# Montana register map
Vendor: ONSemiconductor; Series: Montana Series; File version: 1.0
CPU: CM33 r0p4, little endian, MPU, FPU, 3 interrupt priority bits
Registers are 32-bit, read-write, reset 0x0 unless marked. A register's access mark holds for its fields unless they carry their own. Offsets are from the block's base; [hi:lo] are bit positions; {n}, {i} and the like mark numbered series.

## NFC — NFC Controller
Base 0x40040000
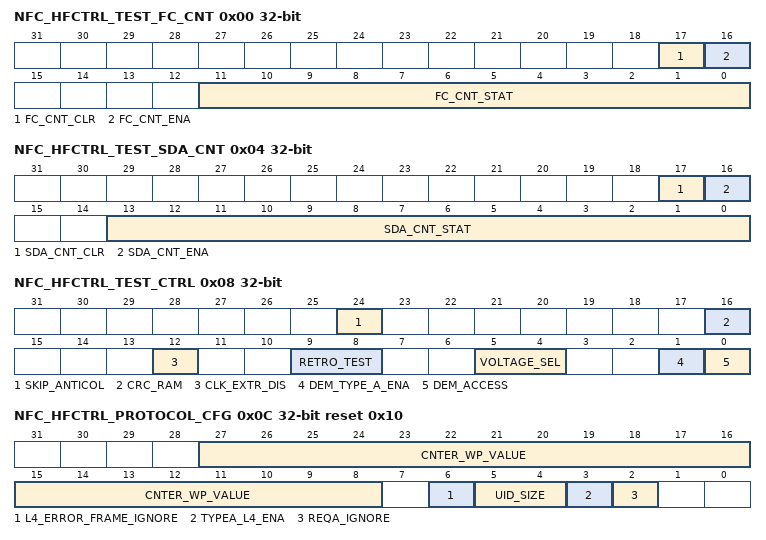
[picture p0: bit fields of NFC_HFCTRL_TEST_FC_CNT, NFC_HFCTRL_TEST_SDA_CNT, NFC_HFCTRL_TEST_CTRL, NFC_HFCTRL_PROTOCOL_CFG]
0x00 NFC_HFCTRL_TEST_FC_CNT — TEST Fc COUNTER Register
  [17] FC_CNT_CLR — Pulse to clear the FC_CNT_STATUS value to 0xFFF Set Only by SW; reset by HW
    0=FC_CNT_NOT_CLR; 1=FC_CNT_CLR
  [16] FC_CNT_ENA — Stop/decounting the decounter
    0=FC_CNT_STOP; 1=FC_CNT_DECOUNTING
  [11:0] FC_CNT_STAT ro — Fc clock counter status
    0=FC_CNT_STATUS_VALUE
0x04 NFC_HFCTRL_TEST_SDA_CNT — TEST SDA COUNTER Register
  [17] SDA_CNT_CLR — Pulse to clear the SDA_CNT_STATUS value to 0x0000. Set Only by SW; reset by HW
    0=SDA_CNT_NOT_CLR; 1=SDA_CNT_CLR
  [16] SDA_CNT_ENA — SDA counter enable
    0=SDA_CNT_STOP (The counter is stopped); 1=SDA_CNT_COUNTING (The counter is counting)
  [13:0] SDA_CNT_STAT ro — SDA clock counter
    0=SDA_CNT_STATUS_VALUE
0x08 NFC_HFCTRL_TEST_CTRL — TEST CTRL Register
  [24] SKIP_ANTICOL — 0 : When ISO Type A; the Layer 3 anti-collision sequence is managed by the HW FSM 1 : When ISO Type A; the Layer 3 anti-collision sequence is skipped with direct SW access
    0=ANTICOL_MANAGED; 1=ANTICOL_SKIPPED
  [16] CRC_RAM — 1 : The CRC is taken from the last 2 bytes of the IO RAM buffer (TEST mode) 0 : The FSM generates on the fly the CRC from the data information present inside the IO RAM buffer
    0=CRC_READ_FROM_RAM; 1=CRC_PROCESS
  [12] CLK_EXTR_DIS — When 1; the clock extractor of the Analog Front end is disabled (power saving configuration when HF not used)
    0=CLK_EXTRACTOR_ENABLED; 1=CLK_EXTRACTOR_DISABLED
  [9:8] RETRO_TEST — retromodulation control testing features 00 : retro is monitored by the FSM 01 : retro=1 (TEST mode or power saving configuration when HF not used) 10 : retro=Fc/16 (TEST mode) 11 : retro=Fc/8 (TEST mode)
    0=FSM_CTRL_RETRO; 1=RETRO_SET; 2=RETRO_AT_FC_DIV_16; 3=RETRO_AT_FC_DIV_8
  [5:4] VOLTAGE_SEL — Voltage selection for Analog Testing PAD redirection
    0=SEL_HIGH_Z; 1=SEL_VDC; 2=SEL_VDDA
  [1] DEM_TYPE_A_ENA — Only active when DEM_ACCESS=1 1 : Enable the demodulator Type A analog front-end (Rx) 0 : Disable the demodulator Type A analog front-end
    0=DEM_TYPE_A_DISABLED; 1=DEM_TYPE_A_ENABLED
  [0] DEM_ACCESS — 1 : The SW has the hand to enable or disable the demodulators (TEST mode) 0 : The FSM of the digital controller has the hand on demodulators activation according to PROTOCOL_CFG.TYPE
    0=HW_DEM_ACCESS; 1=SW_DEM_ACCESS
0x0C NFC_HFCTRL_PROTOCOL_CFG reset 0x10 — PROTOCOL and COMMUNICATION CONFIG register
  [27:8] CNTER_WP_VALUE — Slot counter watchpoint value (FDT PCD to PICC)
    0=CNTER_WP_RESET_VALUE
  [6] L4_ERROR_FRAME_IGNORE — Layer 4 Transmission Error frame ignore
    0=L4_ERROR_FRAME_REPORT_ALL; 1=L4_ERROR_FRAME_IGNORE
  [5:4] UID_SIZE — UID size when Type A (Layer 3) 01: UID size=1 10: UID size=2 11: UID size=3 00: not applicable
  [3] TYPEA_L4_ENA — The SW shall set this bit to 1 when entering in ISO Type A Layer 4 0: only 64 bytes are available for SW (0xE000-0xE0FF) 1: the 1 Kbytes of the IO RAM are available Autoclear by HW when BACK_TO_HALT
    0=TYPEA_L4_DISABLED; 1=TYPEA_L4_ENABLED
  [2] REQA_IGNORE — The SW shall set this bit to 1 after the first valid RATS or C-RATS 0: a BACK_TO_HALT will make the HW FSM in IDLE state (like after POR). 1: a BACK_TO_HALT will make the HW FSM in HALT state.
    0=BACK_TO_IDLE; 1=BACK_TO_HALT
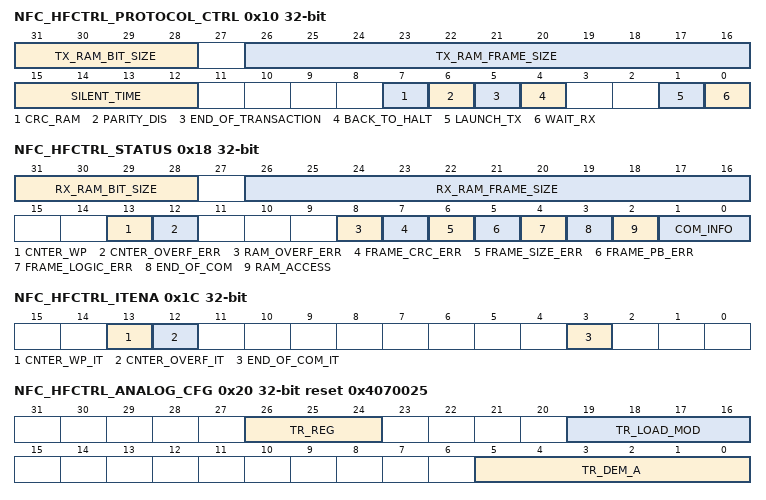
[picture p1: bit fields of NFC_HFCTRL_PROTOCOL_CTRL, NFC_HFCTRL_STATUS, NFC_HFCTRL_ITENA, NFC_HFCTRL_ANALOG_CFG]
0x10 NFC_HFCTRL_PROTOCOL_CTRL — PROTOCOL and COMMUNICATION CTRL Register
  [31:28] TX_RAM_BIT_SIZE — The number of split byte bits sent is 8-TX_RAM_BIT_SIZE
  [26:16] TX_RAM_FRAME_SIZE — IO RAM frame size status for Tx : To be updated by SW before/when LAUNCH_TX
  [15:12] SILENT_TIME — Silent time value for the current communication sequence Defined in number of slots
  [7] CRC_RAM — '1' : Tx only. No CRC bytes added at end of frame, final size is TX_RAM_FRAME_SIZE
    1=CRC_RAM_DISABLED
  [6] PARITY_DIS — '1' : Tx only. Parity bit is not sent
    1=PARITY_DISABLED
  [5] END_OF_TRANSACTION — Indicates the end of transaction
    1=END_OF_TRANSACTION
  [4] BACK_TO_HALT — When 1: Allows to return in IDLE/HALT ISO Type A layer 3 - If launched with WAIT_RX: PICC mode is in HALT or IDLE state immediately - If launched with LAUNCH_TX: the HALT or IDLE state will be reached after the end of the Tx frame The IDLE or HALT state is chosen with the REQA_IGNORE configuration Set Only by SW; reset by HW
    1=RETURN_TO_HALT_OR_IDLE
  [1] LAUNCH_TX — Launch the Tx frame with the IO RAM buffer content after waiting SILENT_TIME slots Set Only by SW; reset by HW
  [0] WAIT_RX — When STATUS.COM_INFO=00; launch the HF digital controller; according to the HFCTRL_PROTOCOL_CFG.TYPE configuration When STATUS.COM_INFO=11; it will force the Tx frame ignorance : the PICC will not answer (mute); the HF digital controller returns in Rx mode This bit shall not be launched when STATUS.COM_INFO=01 or 10 Note that at each WAIT_RX=1; the bit rates configurations are reloaded inside the digital controller Set Only by SW; reset by HW
0x14 NFC_HFCTRL_COUNTER_STATUS ro — SLOT COUNTER STATUS register
  [19:0] CNTER_STATUS — Slot counter status (FDT PDC to PICC)
    0=CNTER_STATUS_VALUE
0x18 NFC_HFCTRL_STATUS ro — STATUS Register
  [31:28] RX_RAM_BIT_SIZE — IO RAM bit size part status when Rx Updated when Rx to Exec period transition
    0=RX_RAM_BIT_SIZE_VALUE
  [26:16] RX_RAM_FRAME_SIZE — IO RAM frame size status when Rx Updated by the HW
    0=RX_RAM_FRAME_SIZE_VALUE
  [13] CNTER_WP — Slot counter Watchpoint flag When 1; the Slot counter has reached the value of the watchpoint in Exec period Clear only by SW
    0=NO_CNT_WP_ERROR; 1=CNT_WP_ERROR
  [12] CNTER_OVERF_ERR — Slot counter Overflow error flag When 1; the Slot counter has reached the maximum value and continues counting from 0 Clear only by SW
    0=NO_CNT_OVERUN_ERROR; 1=CNT_OVERRUN_ERROR
  [8] RAM_OVERF_ERR — IO RAM overflow error flag When 1; the complete 1KB IO RAM buffer has been filled by the Rx frame Clear only by SW
    1=RAM_FULL
  [7] FRAME_CRC_ERR — Bad frame CRC error flag : CRC on two bytes; done in the whole byte of the frame (ISO type B / ISO type A layer 4) in Rx When 1; a CRC error has been detected Clear only by SW
    0=NO_CRC_ERROR; 1=CRC_ERROR
  [6] FRAME_SIZE_ERR — Frame size error flag : not standard frame size (ISO type B / ISO type A layer 4) in Rx. When 1; a frame size error has been detected Clear only by SW
    0=NO_FRAME_SIZE_ERROR; 1=FRAME_SIZE_ERROR
  [5] FRAME_PB_ERR — Parity bit error flag when ISO type B / ISO type A layer 4 Rx When 1; a parity bit error has been detected inside the frame Clear only by SW
    0=NO_PARITY_ERROR; 1=PARITY_ERROR
  [4] FRAME_LOGIC_ERR — Logic error flag when ISO type B / ISO type A layer 4 Rx When 1; an logic bit error has been detected inside the frame Clear only by SW
    0=NO_LOGIC_ERROR; 1=LOGIC_ERROR
  [3] END_OF_COM — When '1', the Rx period has finished (end of reception) or the Tx transmission has finished with the end of transaction feature activated. It is only updated with the presence of the SClk and it is automatically set/reset by HW.
    0=NOT_END_OF_COM
  [2] RAM_ACCESS — IO RAM access right for SW status When 1: The IO RAM can be accessed by SW for read and write
    0=SW_CAN_T_ACCESS_RAM; 1=SW_COULD_ACCESS_RAM
  [1:0] COM_INFO — Communication state status 00: Digital controller not launched (HFCTRL_PROTOCOL_CTRL .WAIT_RX) 01: Rx state 10: Tx state 11: Exec state Whatever the layer is.
    0=IDLE_STATE; 1=RX_STATE; 2=TX_STATE; 3=EXEC_STATE
0x1C NFC_HFCTRL_ITENA — ITENA Interrupt enable register
  [13] CNTER_WP_IT — 1: An interruption is raised when CNTER_WP set to 1 0: The interruption for this flag is disabled
    0=CNT_WP_INT_DISABLE; 1=CNT_WP_INT_ENABLE
  [12] CNTER_OVERF_IT — 1: An interruption is raised when CNTER_OVERF_ERR set to 1 0: The interruption for this flag is disabled
    0=CNT_OVERRUN_INT_DISABLE; 1=CNT_OVERRUN_INT_ENABLE
  [3] END_OF_COM_IT — 1: An interruption is raised when END_OF_COM set to '1' 0: The interruption for this flag is disabled
    0=END_OF_COM_INT_DISABLE; 1=END_OF_COM_INT_ENABLE
0x20 NFC_HFCTRL_ANALOG_CFG reset 0x4070025 — ANALOG FRONTEND CONFIG register
  [26:24] TR_REG — Configuration of the Voltage regulator
    4=TR_REG_RESET_VALUE
  [19:16] TR_LOAD_MOD — Configuration of the load modulation level (Tx)
    7=TR_LOAD_MOD_RESET_VALUE
  [5:0] TR_DEM_A — Configuration for type A demodulator (Rx)
    37=TR_DEM_A_RESET_VALUE
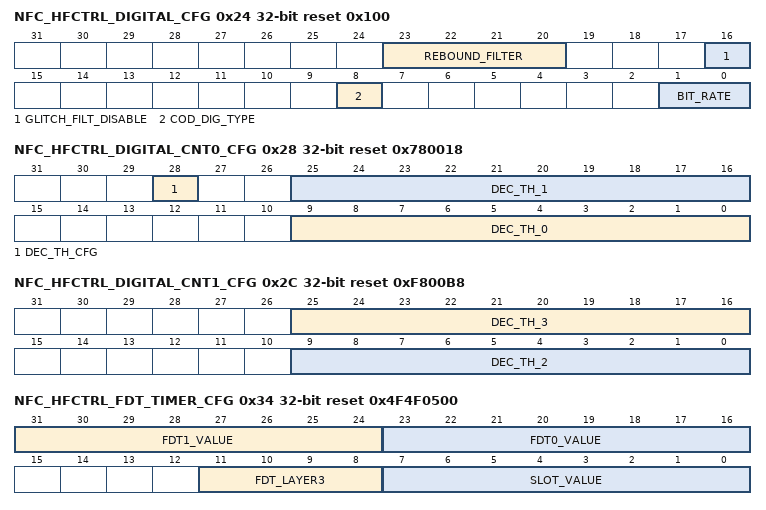
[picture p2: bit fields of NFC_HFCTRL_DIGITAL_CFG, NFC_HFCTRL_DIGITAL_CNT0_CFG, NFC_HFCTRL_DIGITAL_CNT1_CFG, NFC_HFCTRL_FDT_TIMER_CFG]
0x24 NFC_HFCTRL_DIGITAL_CFG reset 0x100 — DIGITAL FRONTEND CONFIG register
  [23:20] REBOUND_FILTER — Rebound filter for SDA_A pulse
  [16] GLITCH_FILT_DISABLE — RX glitch filter disable
    0=GLITCH_FILTER_ENABLE; 1=GLITCH_FILTER_DISABLE
  [8] COD_DIG_TYPE — Digital encodeur type selection (Tx)
    0=MODULATION_OOK_MANCHESTER; 1=MODULATION_BPSK_NRZ_L
  [1:0] BIT_RATE — Bit rate selection for Tx
    0=BIT_RATE_FC_DIV_128; 1=BIT_RATE_FC_DIV_64; 2=BIT_RATE_FC_DIV_32
0x28 NFC_HFCTRL_DIGITAL_CNT0_CFG reset 0x780018 — DIGITAL FRONTEND TRIM COUNTER0 register
  [28] DEC_TH_CFG — When the demodulation is ASK 100 percent Modified Miller only: When '1': allows to count with Fc when texttt{sda_a} is down
    0=DEC_TH_CFG_RESET_VALUE
  [25:16] DEC_TH_1 — When the demodulation is ASK 100 percent Modified Miller only: Logic counter threshold 1 (Rx)
    120=DEC_TH_1_RESET_VALUE
  [9:0] DEC_TH_0 — When the demodulation is ASK 100 percent Modified Miller only: Logic counter threshold 0 (Rx)
    24=DEC_TH_0_RESET_VALUE
0x2C NFC_HFCTRL_DIGITAL_CNT1_CFG reset 0xF800B8 — DIGITAL FRONTEND TRIM COUNTER1 register
  [25:16] DEC_TH_3 — When the demodulation is ASK 100 percent Modified Miller only: Logic counter threshold 3 (Rx)
    248=DEC_TH_3_RESET_VALUE
  [9:0] DEC_TH_2 — When the demodulation is ASK 100 percent Modified Miller only: Logic counter threshold 2 (Rx)
    184=DEC_TH_2_RESET_VALUE
0x30 NFC_HFCTRL_DIGITAL_CNT2_CFG reset 0x30F — DIGITAL FRONTEND TRIM COUNTER2 register
  [9:0] DEC_TH_4 — When the demodulation is ASK 100 percent Modified Miller only: Logic counter threshold 4 (Rx) - NOT USED
    0x30F=DEC_TH_4_RESET_VALUE
0x34 NFC_HFCTRL_FDT_TIMER_CFG reset 0x4F4F0500 — SLOT TIMER and FDT CONFIG register
  [31:24] FDT1_VALUE — Offset following a 1 before the first slot - granularity 1/Fc - FDT definition
    79=FDT1_RESET_VALUE
  [23:16] FDT0_VALUE — Offset following a 0 before the first slot - granularity 1/Fc - FDT definition
    79=FDT0_RESET_VALUE
  [11:8] FDT_LAYER3 — FDT for Layer 3
    5=FDT_LAYER3_RESET_VALUE
  [7:0] SLOT_VALUE — Slot Value (128/Fc) - FDT definition
    0=SLOT_RESET_VALUE
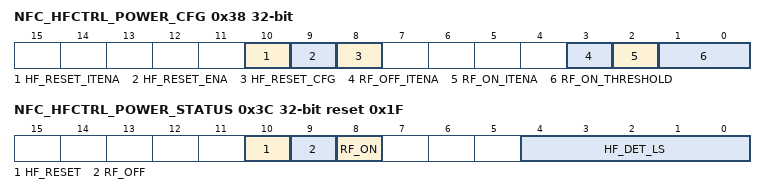
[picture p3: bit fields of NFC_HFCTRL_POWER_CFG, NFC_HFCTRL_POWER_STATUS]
0x38 NFC_HFCTRL_POWER_CFG — POWER CONFIG register
  [10] HF_RESET_ITENA — When '1', enables an interrupt when HFCTRL_POWER_STATUS.HF_RESET is set
    0=HF_RESET_INTERRUPT_DISABLE; 1=HF_RESET_INTERRUPT_ENABLE
  [9] HF_RESET_ENA — When '1', a HF reset is triggered. Set only by SW
    0=HF_RESET_NOT_TRIGGERED; 1=HF_RESET_TRIGGERED
  [8] HF_RESET_CFG — When '1', a HF reset will be triggered at each RF_ON event
    0=HF_RESET_NOT_TRIGGERED_EACH_RF_ON; 1=HF_RESET_TRIGGERED_EACH_RF_ON
  [3] RF_OFF_ITENA — When '1', enables an interrupt when HFCTRL_POWER_STATUS.RF_OFF is set
    0=RF_OFF_INTERRUPT_DISABLE; 1=RF_OFF_INTERRUPT_ENABLE
  [2] RF_ON_ITENA — When '1', enables an interrupt when HFCTRL_POWER_STATUS.RF_ON is set
    0=RF_ON_INTERRUPT_DISABLE; 1=RF_ON_INTERRUPT_ENABLE
  [1:0] RF_ON_THRESHOLD — Configuration of the threshold for RF_ON detection, depending on the HF_DET_LS[2:0]
    0=RF_ON_THRESHOLD_110; 1=RF_ON_THRESHOLD_100; 2=RF_ON_THRESHOLD_000
0x3C NFC_HFCTRL_POWER_STATUS ro reset 0x1F — POWER STATUS register
  [10] HF_RESET — When '1', a HF RESET event occurred.
    1=HF_RESET_EVENT_CLEAR
  [9] RF_OFF — When '1', a RF OFF event occurred.
    1=RF_OFF_EVENT_CLEAR
  [8] RF_ON — When '1', a RF ON event occurred.
    1=RF_ON_EVENT_CLEAR
  [4:0] HF_DET_LS — HF_DET_LS from AFE after system clock synchronization
    31=HF_DET_LS_RESET_VALUE
